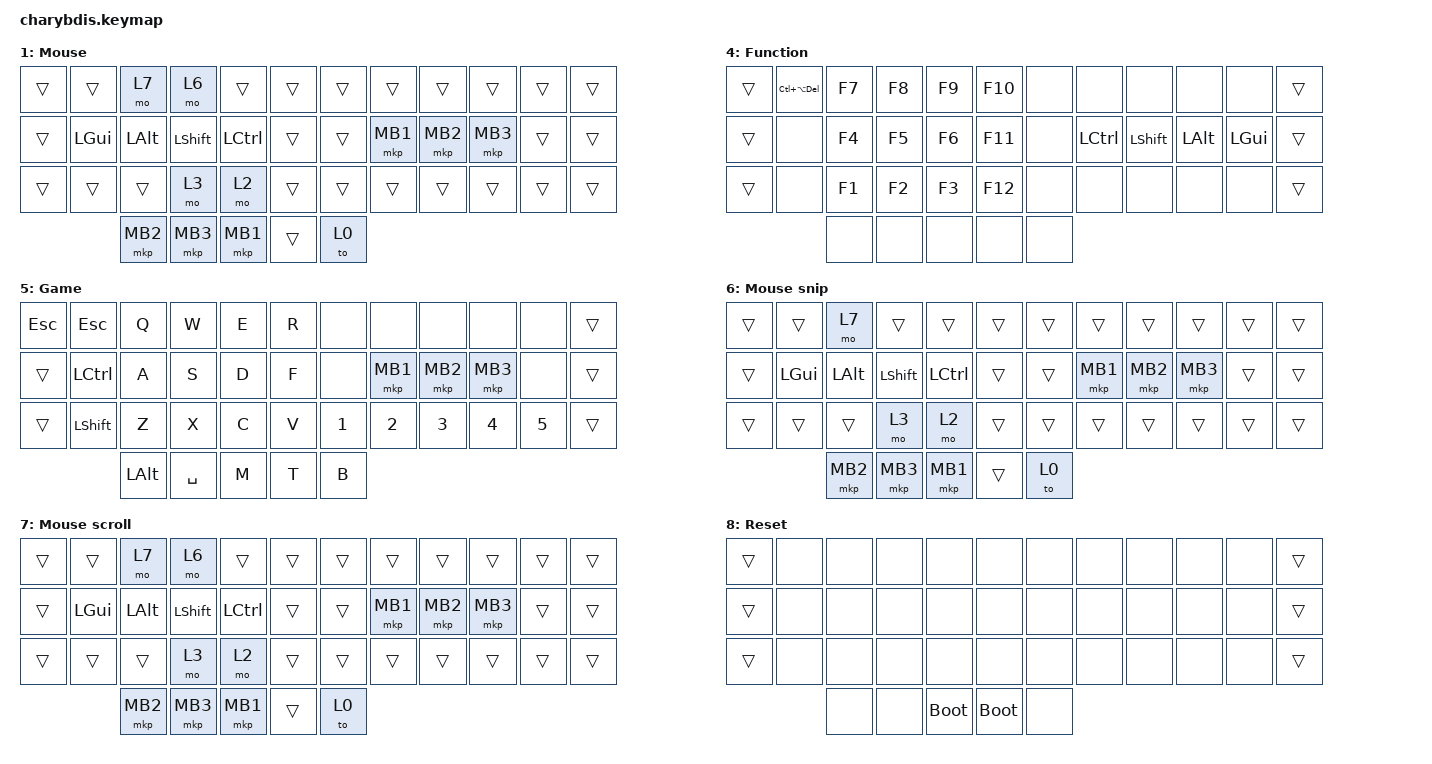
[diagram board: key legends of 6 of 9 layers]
#include <behaviors.dtsi>
#include <dt-bindings/zmk/keys.h>
#include <dt-bindings/zmk/pointing.h>

#define BASE 0
#define MOUSE 1
#define SYMBOL 2
#define NUMBER 3
#define FUNCTION 4
#define GAME 5
#define RESET 6

#define KEYS_L 0 1 2 3 4 10 11 12 13 14 20 21 22 23 24  
#define KEYS_R 5 6 7 8 9 15 16 17 18 19 25 26 27 28 29
#define THUMBS 30 31 32 33 34 35  

&sk {
  release-after-ms = <600>;
  quick-release;
};

&sl {
  ignore-modifiers;
};

&mt {
  flavor = "tap-preferred";
  tapping-term-ms = <120>;
  quick-tap-ms = <180>;
};

&lt {
  flavor = "balanced";
  tapping-term-ms = <120>;
  quick-tap-ms = <180>;
};

&caps_word {
  /delete-property/ ignore-modifiers;
};

/ {
    behaviors {
        gqt: global-quick-tap {
            compatible = "zmk,behavior-hold-tap";
            #binding-cells = <2>;
            flavor = "tap-preferred";
            tapping-term-ms = <120>;
            require-prior-idle-ms = <125>;
            bindings = <&kp>, <&kp>;
            display-name = "Mod-Tap";
        };
    };

    combos {
        compatible = "zmk,combos";

        vpn_toggle {
            bindings = <&kp LS(LG(P))>;
            key-positions = <10 1>;
        };

        web {
            bindings = <&kp RG(S)>;
            key-positions = <12 23>;
        };

        Lang_switch {
            bindings = <&kp RG(SPACE)>;
            key-positions = <16 19>;
        };

        close {
            bindings = <&kp LS(LG(Q))>;
            key-positions = <25 34>;
        };

        Editor {
            bindings = <&kp RG(Z)>;
            key-positions = <28 31>;
        };

        Save {
            bindings = <&kp LC(S)>;
            key-positions = <16 22>;
        };

        Messenger {
            bindings = <&kp RG(A)>;
            key-positions = <4 7>;
        };

        Cmd {
            bindings = <&kp RG(X)>;
            key-positions = <3 8>;
        };

        Ctrl_p {
            bindings = <&kp RC(P)>;
            key-positions = <13 22>;
        };

        arrow {
            bindings = <&arrow>;
            key-positions = <9 2>;
        };

        Change_win {
            bindings = <&kp LA(TAB)>;
            key-positions = <27 32>;
        };

        fat_arrow {
            bindings = <&fat_arrow>;
            key-positions = <26 33>;
        };

        vpn2_toggle {
            bindings = <&kp LS(LG(Y))>;
            key-positions = <25 34>;
        };

        search {
            bindings = <&kp LC(F12)>;
            key-positions = <37 40>;
        };
    };

    macros {
        arrow: arrow {
            compatible = "zmk,behavior-macro";
            #binding-cells = <0>;
            bindings =
                <&macro_tap>,
                <&kp MINUS &kp GREATER_THAN>;
        };
        fat_arrow: fat_arrow {
            compatible = "zmk,behavior-macro";
            #binding-cells = <0>;
            bindings =
                <&macro_tap>,
                <&kp EQUAL &kp GREATER_THAN>;
        };
    };


  chosen {
    zmk,physical-layout = &charybdis_6col_layout;
  };

  keymap {
    compatible = "zmk,keymap";

    Base {
      
      display-name = "Base";

      bindings = <
&kp TAB        &kp Q     &lt 7 W     &lt 1 E  &lt 6 R  &kp T                                 &kp Y  &kp U  &kp I  &kp O  &kp P  &kp LBKT    
&kp LGUI       &kp A     &kp S     &kp D  &gqt LEFT_CONTROL F  &gqt LEFT_ALT G         &kp H  &kp J  &kp K  &kp L  &kp SEMICOLON  &mt LEFT_CONTROL SINGLE_QUOTE  
&kp RGUI       &kp Z     &kp X     &kp C  &kp V                                        &kp B  &kp N  &kp M  &kp COMMA  &kp DOT  &kp SLASH  &mt LEFT_ALT ESC  
                &mt LEFT_GUI DELETE  &lt 2 DEL  &mt LEFT_SHIFT SPACE                   &mt LEFT_SHIFT ENTER  &lt 3  BACKSPACE  &kp RGUI
            >;
    };

    Mouse {
      display-name = "Mouse";
      bindings = <
        &trans   &trans   &mo 7   &mo 6    &trans    &trans            &trans &trans   &trans   &trans   &trans     &trans 
        &trans   &kp LGUI &kp LALT &kp LSHFT &kp LCTRL &trans            &trans &mkp MB1 &mkp MB2 &mkp MB3 &trans     &trans
        &trans   &trans   &trans   &mo 3     &mo 2     &trans            &trans &trans   &trans   &trans   &trans     &trans
                          &mkp MB2  &mkp MB3  &mkp MB1          &trans &to 0
      >;
    };

    Sym {
      display-name = "Symbol";

      bindings = <
&kp RS(INSERT)  &kp EXCLAMATION  &kp AT  &kp HASH  &kp DLLR  &kp PRCNT            &kp CARET  &kp AMPS  &kp STAR  &kp LPAR  &kp RPAR  &kp BSPC
&kp LCTRL  &tog 4  &none  &kp RGUI  &kp BACKSPACE  &tog 3                            &kp MINUS  &kp EQUAL  &kp LBKT  &kp RBKT  &kp BSLH  &kp GRAVE
&kp LALT  &tog 5  &kp LC(X)  &none  &kp LC(LA(P))  &none                          &kp UNDER  &kp PLUS  &kp LBRC  &kp RBRC  &kp PIPE  &kp TILDE
                                           &kp RGUI  &trans  &kp SPACE            &mt LSHFT ENTER  &trans  &kp RALT
      >;
    };

    Num {
      display-name = "Number";

      bindings = <
&kp RC(C)  &kp N1         &kp N2    &kp N3  &kp N4  &kp N5                      &kp N6    &kp N7    &kp N8  &kp N9     &kp N0     &kp SEMICOLON
&kp RC(V)  &kp RC(LS(I))  &kp HOME  &kp END  &kp BACKSPACE  &kp LC(F12)         &kp LEFT  &kp DOWN  &kp UP  &kp RIGHT  &kp MINUS  &mt LEFT_CONTROL F12
&kp RC(X)  &kp F1  &kp F2  &kp F3  &kp F4  &kp F5                               &kp F6    &kp F7    &kp F8  &kp F9     &kp F10    &kp F11
                &kp LC(F3)  &kp LALT  &mt LEFT_CONTROL TAB                      &mt LSHFT ENTER  &trans  &kp SPACE
            >;
    };

    Fun {
      display-name = "Function";
      bindings = <
        &trans    &kp LC(LA(DEL)) &kp F7 &kp F8 &kp F9 &kp F10          &none &none     &none     &none    &none      &trans        
        &trans    &none           &kp F4 &kp F5 &kp F6 &kp F11          &none &kp LCTRL &kp LSHFT &kp LALT &kp LGUI   &trans     
        &trans    &none           &kp F1 &kp F2 &kp F3 &kp F12          &none &none     &none     &none    &none      &trans
                               &none  &none  &none            &none &none
      >;
    };

    Button {
      display-name = "Game";
      bindings = <
        &kp ESCAPE &kp ESCAPE &kp Q &kp W    &kp E     &kp R          &none  &none    &none    &none    &none   &trans   
        &trans &kp LCTRL  &kp A &kp S    &kp D     &kp F          &none  &mkp MB1 &mkp MB2 &mkp MB3 &none   &trans 
        &trans &kp LSHIFT &kp Z &kp X    &kp C     &kp V          &kp N1 &kp N2   &kp N3   &kp N4   &kp N5  &trans
                         &kp LALT &kp SPACE &kp M          &kp T  &kp B                      
      >;
    };

    MouseSnip {
      display-name = "Mouse snip";
      bindings = <
        &trans   &trans   &mo 7   &trans    &trans    &trans            &trans &trans   &trans   &trans   &trans     &trans 
        &trans   &kp LGUI &kp LALT &kp LSHFT &kp LCTRL &trans            &trans &mkp MB1 &mkp MB2 &mkp MB3 &trans     &trans
        &trans   &trans   &trans   &mo 3     &mo 2     &trans            &trans &trans   &trans   &trans   &trans     &trans
                          &mkp MB2  &mkp MB3  &mkp MB1          &trans &to 0
      >;
    };

    MouseScroll {
      display-name = "Mouse scroll";
      bindings = <
        &trans   &trans   &mo 7   &mo 6    &trans    &trans            &trans &trans   &trans   &trans   &trans     &trans 
        &trans   &kp LGUI &kp LALT &kp LSHFT &kp LCTRL &trans            &trans &mkp MB1 &mkp MB2 &mkp MB3 &trans     &trans
        &trans   &trans   &trans   &mo 3     &mo 2     &trans            &trans &trans   &trans   &trans   &trans     &trans
                          &mkp MB2  &mkp MB3  &mkp MB1          &trans &to 0
      >;
    };

    Reset {
      display-name = "Reset";
      bindings = <
        &trans &none &none &none &none &none                &none &none &none &none &none &trans      
        &trans &none &none &none &none &none                &none &none &none &none &none &trans   
        &trans &none &none &none &none &none                &none &none &none &none &none &trans
                    &none &none &bootloader          &bootloader &none                
      >;
    };
  };
};









